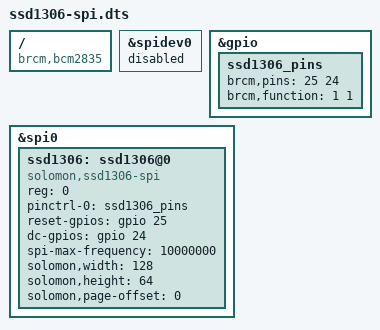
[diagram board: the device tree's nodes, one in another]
/dts-v1/;
/plugin/;

/ {
	compatible = "brcm,bcm2835";
	
	fragment@0 {
		target = <&spidev0>;
		__overlay__ {
			status = "disabled";
		};
	};

	fragment@1 {
		target = <&gpio>;
		__overlay__ {
			ssd1306_pins: ssd1306_pins {
				brcm,pins = <25 24>;
				brcm,function = <1 1>; /* out out */
			};
		};
	};

	fragment@2 {
		target = <&spi0>;
		
		__overlay__ {
			status = "okay";
			#address-cells = <0x01>;
			#size-cells = <0x0>;
			
			ssd1306:ssd1306@0 {
				compatible = "solomon,ssd1306-spi";
				reg = <0>;
				pinctrl-names = "default";
				pinctrl-0 = <&ssd1306_pins>;

				reset-gpios = <&gpio 25 0>;
				dc-gpios = <&gpio 24 0>;

				spi-max-frequency = <10000000>;
				solomon,width = <128>;
				solomon,height = <64>;
				solomon,page-offset = <0>;
			};
		};
	};
};
